# HC32F460PCTB register map
File version: 1.0
CPU: CM4 r0p1, little endian, MPU, FPU, 4 interrupt priority bits
Registers are 32-bit, read-write, reset 0x0 unless marked. A register's access mark holds for its fields unless they carry their own. Offsets are from the block's base; lines under a group give offsets from that group; [hi:lo] are bit positions; {n}, {i} and the like mark numbered series; 'fields as' and 'values as' point back to an identical list; <NAME> marks a mode.

## Memory map
0x00000400 ICG size 0x20
0x40008000 AES size 0x30
0x40008400 HASH size 0x80
0x40008C00 CRC size 0x100
0x40010400 EFM size 0x208
0x40010800 AOS size 0x174
0x40015000 TMRA1 size 0x160 — desc TMRA
0x40015400 TMRA2 size 0x160 — desc TMRA
0x40015800 TMRA3 size 0x160 — desc TMRA
0x40015C00 TMRA4 size 0x160 — desc TMRA
0x40016000 TMRA5 size 0x160 — desc TMRA
0x40016400 TMRA6 size 0x160 — desc TMRA
0x40017000 TMR41 size 0xF2 — desc TMR4
0x40017C00 EMB0 size 0x18 — desc EMB
0x40017C20 EMB1 size 0x18 — desc EMB
0x40017C40 EMB2 size 0x18 — desc EMB
0x40017C60 EMB3 size 0x18 — desc EMB
0x40018000 TMR61 size 0x90 — desc TMR6
0x40018300 TMR6_COMMON size 0x100
0x40018400 TMR62 size 0x90 — desc TMR6
0x40018800 TMR63 size 0x90 — desc TMR6
0x4001C000 SPI1 size 0x1C — desc SPI
0x4001C400 SPI2 size 0x1C — desc SPI
0x4001D000 USART1 size 0x1C — desc USART
0x4001D400 USART2 size 0x1C — desc USART
0x4001E000 I2S1 size 0x1C — desc I2S
0x4001E400 I2S2 size 0x1C — desc I2S
0x40020000 SPI3 size 0x1C — desc SPI
0x40020400 SPI4 size 0x1C — desc SPI
0x40021000 USART3 size 0x1C — desc USART
0x40021400 USART4 size 0x1C — desc USART
0x40022000 I2S3 size 0x1C — desc I2S
0x40022400 I2S4 size 0x1C — desc I2S
0x40024000 TMR01 size 0x18 — desc TMR0
0x40024400 TMR02 size 0x18 — desc TMR0
0x40024800 TMR42 size 0xF2 — desc TMR4
0x40024C00 TMR43 size 0xF2 — desc TMR4
0x40040000 ADC1 size 0xD0
0x40040400 ADC2 size 0xB2
0x40041000 TRNG size 0x14
0x40048000 PWC size 0xC42C
0x40048400 FCM size 0x24
0x40049000 WDT size 0xC
0x40049400 SWDT size 0xC
0x4004A000 CMP1 size 0xA — desc CMP
0x4004A000 CMP_COMMON size 0x10E
0x4004A010 CMP2 size 0xA — desc CMP
0x4004A020 CMP3 size 0xA — desc CMP
0x4004A400 OTS size 0xC
0x4004C000 RTC size 0x40
0x4004E000 I2C1 size 0x34 — desc I2C
0x4004E400 I2C2 size 0x34 — desc I2C
0x4004E800 I2C3 size 0x34 — desc I2C
0x40050000 MPU size 0x4020
0x40050800 SRAMC size 0x14
0x40050C00 KEYSCAN size 0xC
0x40051000 INTC size 0x2A8
0x40052000 DCU1 size 0x1C — desc DCU
0x40052400 DCU2 size 0x1C — desc DCU
0x40052800 DCU3 size 0x1C — desc DCU
0x40052C00 DCU4 size 0x1C — desc DCU
0x40053000 DMA1 size 0x120 — desc DMA
0x40053400 DMA2 size 0x120 — desc DMA
0x40053800 GPIO size 0x54C
0x40054000 CMU size 0x42A
0x400540C0 RMU size 0x2
0x40055400 PERIC size 0x8
0x40055408 TMR4_ECER size 0xC
0x4006FC00 SDIOC1 size 0x54 — desc SDIOC
0x40070000 SDIOC2 size 0x54 — desc SDIOC
0x40070400 CAN size 0xCA
0x400C0000 USBFS size 0xE04
0x9C000000 QSPI size 0x808
0xE0042000 DBGC size 0x28

## ADC1
Base 0x40040000
0x00 STR 8-bit
  [0] STRT
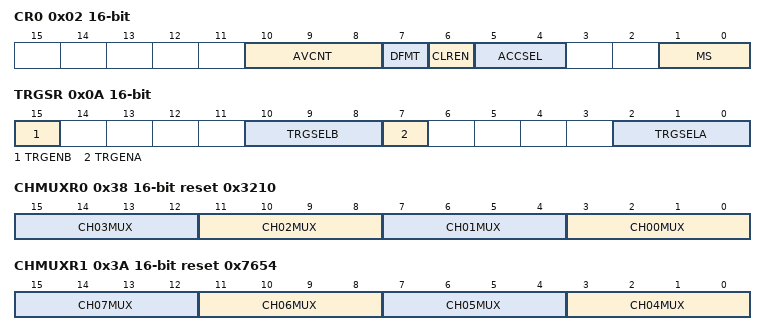
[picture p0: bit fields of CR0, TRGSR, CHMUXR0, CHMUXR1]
0x02 CR0 16-bit
  [10:8] AVCNT, [7] DFMT, [6] CLREN, [5:4] ACCSEL, [1:0] MS
0x04 CR1 16-bit
  [2] RSCHSEL
0x0A TRGSR 16-bit
  [15] TRGENB, [10:8] TRGSELB, [7] TRGENA, [2:0] TRGSELA
0x0C CHSELRA
  [16:0] CHSELA
0x10 CHSELRB
  [16:0] CHSELB
0x14 AVCHSELR
  [16:0] AVCHSEL
{0x20+i} SSTR{i} 8-bit reset 0xB (i=0..15)
0x30 SSTRL 8-bit reset 0xB
0x38 CHMUXR0 16-bit reset 0x3210
  [4n+3:4n] CH{n:02}MUX (n=0..3)
0x3A CHMUXR1 16-bit reset 0x7654
  [4n-13:4n-16] CH{n:02}MUX (n=4..7)
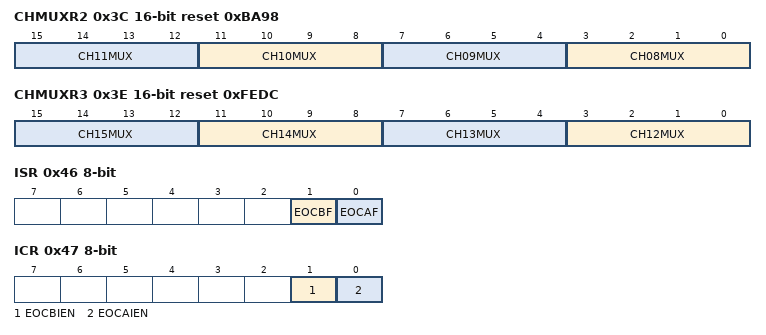
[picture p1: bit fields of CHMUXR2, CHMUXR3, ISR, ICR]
0x3C CHMUXR2 16-bit reset 0xBA98
  [4n-29:4n-32] CH{n:02}MUX (n=8..11)
0x3E CHMUXR3 16-bit reset 0xFEDC
  [4n-45:4n-48] CH{n}MUX (n=12..15)
0x46 ISR 8-bit
  [1] EOCBF, [0] EOCAF
0x47 ICR 8-bit
  [1] EOCBIEN, [0] EOCAIEN
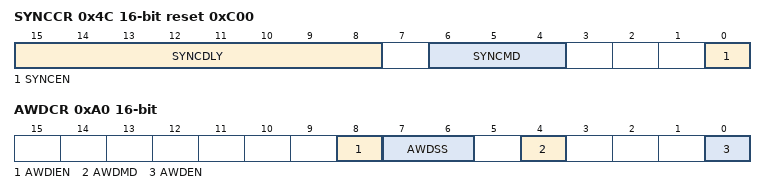
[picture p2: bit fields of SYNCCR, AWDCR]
0x4C SYNCCR 16-bit reset 0xC00
  [15:8] SYNCDLY, [6:4] SYNCMD, [0] SYNCEN
{0x50+2i} DR{i} 16-bit ro (i=0..16)
0xA0 AWDCR 16-bit
  [8] AWDIEN, [7:6] AWDSS, [4] AWDMD, [0] AWDEN
0xA4 AWDDR0 16-bit
0xA6 AWDDR1 16-bit
0xAC AWDCHSR
  [16:0] AWDCH
0xB0 AWDSR
  [16:0] AWDF
0xC0 PGACR 16-bit
  [3:0] PGACTL
0xC2 PGAGSR 16-bit
  [3:0] GAIN
0xCC PGAINSR0 16-bit
  [8:0] PGAINSEL
0xCE PGAINSR1 16-bit
  [0] PGAVSSEN

## ADC2
Base 0x40040400
Registers as ADC1, without SSTR{n} (n=9..15), SSTRL, CHMUXR3, SYNCCR, DR{n} (n=9..16), PGACR, PGAGSR, PGAINSR0, PGAINSR1; these are added or differ:
0x0C CHSELRA
  [8:0] CHSELA
0x10 CHSELRB
  [8:0] CHSELB
0x14 AVCHSELR
  [8:0] AVCHSEL
0x3C CHMUXR2 16-bit reset 0xBA98
  [3:0] CH08MUX
0xAC AWDCHSR
  [8:0] AWDCH
0xB0 AWDSR
  [8:0] AWDF
